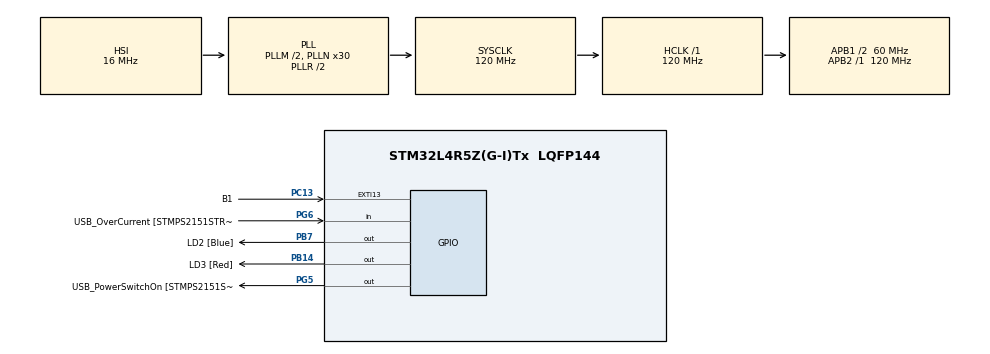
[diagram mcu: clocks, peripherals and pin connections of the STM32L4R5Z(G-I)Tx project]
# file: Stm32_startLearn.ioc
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Mcu.Family=STM32L4
RCC.CortexFreq_Value=120000000
PG6.Signal=GPIO_Input
PH0-OSC_IN\ (PH0).Signal=RCC_OSC_IN
PG8.Signal=LPUART1_RX
PB14.GPIO_Label=LD3 [Red]
PG6.GPIO_Label=USB_OverCurrent [STMPS2151STR_FAULT]
RCC.SYSCLKSourceVirtual=RCC_SYSCLKSOURCE_PLLCLK
PC15-OSC32_OUT\ (PC15).Mode=LSE-External-Oscillator
PC13.GPIO_Label=B1
PG5.GPIO_Label=USB_PowerSwitchOn [STMPS2151STR_EN]
RCC.SYSCLKSource=RCC_SYSCLKSOURCE_PLLCLK
ProjectManager.StackSize=0x400
PC14-OSC32_IN\ (PC14).Mode=LSE-External-Oscillator
PA14\ (JTCK/SWCLK).Signal=SYS_JTCK-SWCLK
PA12.Signal=USB_OTG_FS_DP
RCC.HCLKFreq_Value=120000000
RCC.APB2TimFreq_Value=120000000
PD8.Signal=USART3_TX
RCC.AHBFreq_Value=120000000
RCC.HSE_VALUE=8000000
RCC.PLLMUL=RCC_PLL_MUL9
PA13\ (JTMS/SWDIO).GPIO_Label=TMS
PA10.GPIO_Label=USB_ID
PB7.Signal=GPIO_Output
PA8.Signal=USB_OTG_FS_SOF
PA14\ (JTCK/SWCLK).Mode=Trace_Asynchronous_SW
PB7.GPIO_Label=LD2 [Blue]
Mcu.Package=LQFP144
PA10.Signal=USB_OTG_FS_ID
PA14\ (JTCK/SWCLK).GPIO_Label=TCK
RCC.APB1TimFreq_Value=120000000
RCC.CK48CLockSelection=RCC_USBCLKSOURCE_HSI48
RCC.HSI48_VALUE=48000000
RCC.PLLSAI1N=12
PB3\ (JTDO/TRACESWO).GPIO_Label=SWO
RCC.MSI_VALUE=4000000
RCC.PLLSourceVirtual=RCC_PLLSOURCE_HSI
PG7.Signal=LPUART1_TX
PA13\ (JTMS/SWDIO).Mode=Trace_Asynchronous_SW
PD9.GPIO_Label=STLK_TX [STM32F103CBT6_PA2]
PG5.Signal=GPIO_Output
PC13.Signal=GPXTI13
PA9.GPIO_Label=USB_VBUS
PA11.GPIO_Label=USB_DM
PD9.Signal=USART3_RX
PC15-OSC32_OUT\ (PC15).Signal=RCC_OSC32_OUT
RCC.APB1CLKDivider=RCC_HCLK_DIV2
PA12.GPIO_Label=USB_DP
PH1-OSC_OUT\ (PH1).Signal=RCC_OSC_OUT
PD8.GPIO_Label=STLK_RX [STM32F103CBT6_PA3]
PG8.GPIO_Label=STLINK_RX
PA8.GPIO_Label=USB_SOF [TP1]
PB3\ (JTDO/TRACESWO).Signal=SYS_JTDO-SWO
ProjectManager.TargetToolchain=STM32CubeIDE
PA9.Signal=USB_OTG_FS_VBUS
RCC.USBFreq_Value=48000000
PB14.Signal=GPIO_Output
board=NUCLEO-L4R5ZI
RCC.VCOOutputFreq_Value=240000000
RCC.APB2Freq_Value=120000000
RCC.PRESCALERUSB=RCC_USBCLKSOURCE_PLL_DIV1_5
PG7.GPIO_Label=STLINK_TX
RCC.ADCFreq_Value=96000000
Mcu.Name=STM32L4R5Z(G-I)Tx
RCC.48MHZClocksFreq_Value=24000000
RCC.SYSCLKFreq_VALUE=120000000
RCC.PLLM1=2
PC14-OSC32_IN\ (PC14).Signal=RCC_OSC32_IN
PA11.Signal=USB_OTG_FS_DM
ProjectManager.HeapSize=0x200
RCC.HSI_VALUE=16000000
NVIC.PriorityGroup=NVIC_PRIORITYGROUP_4
RCC.PLLN=30
PB3\ (JTDO/TRACESWO).Mode=Trace_Asynchronous_SW
RCC.APB1Freq_Value=60000000
PA13\ (JTMS/SWDIO).Signal=SYS_JTMS-SWDIO

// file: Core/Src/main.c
/* USER CODE BEGIN Header */
/**
  ******************************************************************************
  * @file           : main.c
  * @brief          : Main program body
  ******************************************************************************
  * @attention
  *
  * <h2><center>&copy; Copyright (c) 2021 STMicroelectronics.
  * All rights reserved.</center></h2>
  *
  * This software component is licensed by ST under BSD 3-Clause license,
  * the "License"; You may not use this file except in compliance with the
  * License. You may obtain a copy of the License at:
  *                        opensource.org/licenses/BSD-3-Clause
  *
  ******************************************************************************
  */
/* USER CODE END Header */
#include "main.h"
#include "gpio.h"

void SystemClock_Config(void);

int main(void)
{

  /* MCU Configuration--------------------------------------------------------*/

  /* Reset of all peripherals, Initializes the Flash interface and the Systick. */
  HAL_Init();

  /* Configure the system clock */
  SystemClock_Config();

  /* Initialize all configured peripherals */
  MX_GPIO_Init();

  /* Infinite loop */
  /* USER CODE BEGIN WHILE */
  while (1)
  {
  //  HAL_GPIO_TogglePin(LD2_GPIO_Port, LD2_Pin);
    HAL_GPIO_TogglePin(LD3_GPIO_Port, LD3_Pin);
    HAL_Delay(200);
    /* USER CODE END WHILE */

  }
}

void SystemClock_Config(void)
{
  RCC_OscInitTypeDef RCC_OscInitStruct = {0};
  RCC_ClkInitTypeDef RCC_ClkInitStruct = {0};

  /** Configure the main internal regulator output voltage
  */
  if (HAL_PWREx_ControlVoltageScaling(PWR_REGULATOR_VOLTAGE_SCALE1_BOOST) != HAL_OK)
  {
    Error_Handler();
  }
  /** Initializes the RCC Oscillators according to the specified parameters
  * in the RCC_OscInitTypeDef structure.
  */
  RCC_OscInitStruct.OscillatorType = RCC_OSCILLATORTYPE_HSI;
  RCC_OscInitStruct.HSIState = RCC_HSI_ON;
  RCC_OscInitStruct.HSICalibrationValue = RCC_HSICALIBRATION_DEFAULT;
  RCC_OscInitStruct.PLL.PLLState = RCC_PLL_ON;
  RCC_OscInitStruct.PLL.PLLSource = RCC_PLLSOURCE_HSI;
  RCC_OscInitStruct.PLL.PLLM = 2;
  RCC_OscInitStruct.PLL.PLLN = 30;
  RCC_OscInitStruct.PLL.PLLP = RCC_PLLP_DIV2;
  RCC_OscInitStruct.PLL.PLLQ = RCC_PLLQ_DIV2;
  RCC_OscInitStruct.PLL.PLLR = RCC_PLLR_DIV2;
  if (HAL_RCC_OscConfig(&RCC_OscInitStruct) != HAL_OK)
  {
    Error_Handler();
  }
  /** Initializes the CPU, AHB and APB buses clocks
  */
  RCC_ClkInitStruct.ClockType = RCC_CLOCKTYPE_HCLK|RCC_CLOCKTYPE_SYSCLK
                              |RCC_CLOCKTYPE_PCLK1|RCC_CLOCKTYPE_PCLK2;
  RCC_ClkInitStruct.SYSCLKSource = RCC_SYSCLKSOURCE_PLLCLK;
  RCC_ClkInitStruct.AHBCLKDivider = RCC_SYSCLK_DIV1;
  RCC_ClkInitStruct.APB1CLKDivider = RCC_HCLK_DIV2;
  RCC_ClkInitStruct.APB2CLKDivider = RCC_HCLK_DIV1;

  if (HAL_RCC_ClockConfig(&RCC_ClkInitStruct, FLASH_LATENCY_5) != HAL_OK)
  {
    Error_Handler();
  }
}

void Error_Handler(void)
{
  __disable_irq();
  while (1)
  {
  }
}

/************************ (C) COPYRIGHT STMicroelectronics *****END OF FILE****/
